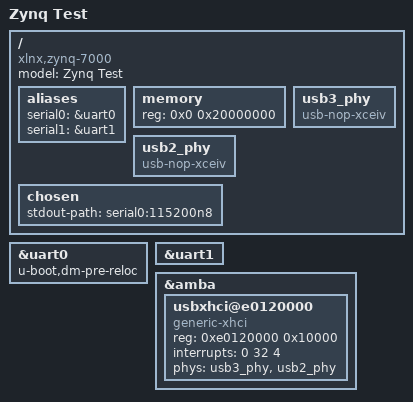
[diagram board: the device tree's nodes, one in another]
// SPDX-License-Identifier: GPL-2.0+
/dts-v1/;
#include "xilinx/zynq-7000.dtsi"

/ {
	model = "Zynq Test";
	compatible = "xlnx,zynq-7000";
	
	aliases {
		serial0 = &uart0;
		serial1 = &uart1;
	};

	memory {
		device_type = "memory";
		reg = <0x0 0x20000000>;
	};

	usb3_phy: usb3_phy {
		compatible = "usb-nop-xceiv";
	};

	usb2_phy: usb2_phy {
		compatible = "usb-nop-xceiv";
	};

	chosen {
		stdout-path = "serial0:115200n8";
	};
};

&uart0 {
	u-boot,dm-pre-reloc;
	status = "okay";
};

&uart1 {
	status = "okay";
};

&amba {
	usbxhci@e0120000 {
		status = "okay";
		compatible = "generic-xhci";
		reg = <0xe0120000 0x10000>;
		interrupts = <0 32 4>;
		phys = <&usb3_phy>, <&usb2_phy>;
				phy-names = "usb3-phy", "usb2-phy";
	};
};
